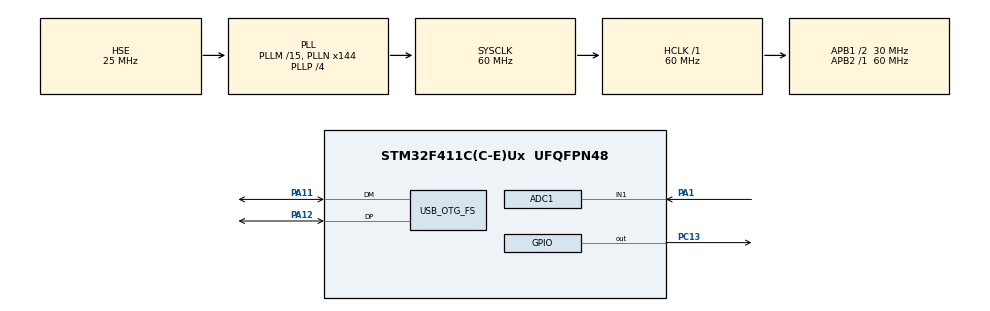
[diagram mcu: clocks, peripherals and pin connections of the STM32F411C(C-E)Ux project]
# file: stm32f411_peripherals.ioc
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ADC1.Channel-0\#ChannelRegularConversion=ADC_CHANNEL_1
ADC1.Channel-1\#ChannelInjectedConversion=ADC_CHANNEL_1
ADC1.ContinuousConvMode=ENABLE
ADC1.InjNumberOfConversion=1
ADC1.InjectedOffset-1\#ChannelInjectedConversion=0
ADC1.InjectedRank-1\#ChannelInjectedConversion=1
ADC1.NbrOfConversionFlag=1
ADC1.Rank-0\#ChannelRegularConversion=1
ADC1.SamplingTime-0\#ChannelRegularConversion=ADC_SAMPLETIME_3CYCLES
ADC1.SamplingTime-1\#ChannelInjectedConversion=ADC_SAMPLETIME_3CYCLES
ADC1.master=1
Mcu.Family=STM32F4
Mcu.Name=STM32F411C(C-E)Ux
Mcu.Package=UFQFPN48
NVIC.ADC_IRQn=true\:0\:0\:false\:false\:true\:true\:true\:true
NVIC.OTG_FS_IRQn=true\:0\:0\:false\:false\:true\:true\:true\:true
NVIC.OTG_FS_WKUP_IRQn=true\:0\:0\:false\:false\:true\:false\:true\:true
NVIC.PriorityGroup=NVIC_PRIORITYGROUP_4
NVIC.TIM1_TRG_COM_TIM11_IRQn=true\:0\:0\:false\:false\:true\:true\:true\:true
PA1.Signal=ADCx_IN1
PA11.Mode=Device_Only
PA11.Signal=USB_OTG_FS_DM
PA12.Mode=Device_Only
PA12.Signal=USB_OTG_FS_DP
PC13-ANTI_TAMP.Signal=GPIO_Output
PC14-OSC32_IN.Mode=LSE-External-Oscillator
PC14-OSC32_IN.Signal=RCC_OSC32_IN
PC15-OSC32_OUT.Mode=LSE-External-Oscillator
PC15-OSC32_OUT.Signal=RCC_OSC32_OUT
PH0\ -\ OSC_IN.Mode=HSE-External-Oscillator
PH0\ -\ OSC_IN.Signal=RCC_OSC_IN
PH1\ -\ OSC_OUT.Mode=HSE-External-Oscillator
PH1\ -\ OSC_OUT.Signal=RCC_OSC_OUT
ProjectManager.HeapSize=0x200
ProjectManager.StackSize=0x400
ProjectManager.TargetToolchain=STM32CubeIDE
RCC.48MHZClocksFreq_Value=48000000
RCC.AHBFreq_Value=60000000
RCC.APB1CLKDivider=RCC_HCLK_DIV2
RCC.APB1Freq_Value=30000000
RCC.APB1TimFreq_Value=60000000
RCC.APB2Freq_Value=60000000
RCC.APB2TimFreq_Value=60000000
RCC.CortexFreq_Value=60000000
RCC.HCLKFreq_Value=60000000
RCC.HSE_VALUE=25000000
RCC.HSI_VALUE=16000000
RCC.PLLM=15
RCC.PLLN=144
RCC.PLLP=RCC_PLLP_DIV4
RCC.PLLQ=5
RCC.RCC_RTC_Clock_Source=RCC_RTCCLKSOURCE_LSI
RCC.RCC_RTC_Clock_SourceVirtual=RCC_RTCCLKSOURCE_LSI
RCC.SYSCLKFreq_VALUE=60000000
RCC.SYSCLKSource=RCC_SYSCLKSOURCE_PLLCLK
RCC.VCOOutputFreq_Value=240000000
SH.ADCx_IN1.0=ADC1_IN1,IN1
TIM11.AutoReloadPreload=TIM_AUTORELOAD_PRELOAD_ENABLE
TIM11.Channel=TIM_CHANNEL_1
TIM11.ClockDivision=TIM_CLOCKDIVISION_DIV1
TIM11.Period=1000
TIM11.Prescaler=1000
USB_DEVICE.CLASS_NAME_FS=CDC
USB_DEVICE.MANUFACTURER_STRING=Bipin
USB_DEVICE.PRODUCT_STRING_CDC_FS=Bipin Virtual ComPort
USB_DEVICE.VirtualMode=Cdc
USB_DEVICE.VirtualModeFS=Cdc_FS
USB_OTG_FS.Sof_enable=ENABLE
USB_OTG_FS.VirtualMode=Device_Only
USB_OTG_FS.low_power_enable=ENABLE
USB_OTG_FS.lpm_enable=ENABLE
VP_TIM11_VS_ClockSourceINT.Mode=Enable_Timer
VP_TIM11_VS_no_output1.Mode=Output Compare1 No Output
VP_USB_DEVICE_VS_USB_DEVICE_CDC_FS.Mode=CDC_FS
board=custom

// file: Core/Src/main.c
/* USER CODE BEGIN Header */
/**
  ******************************************************************************
  * @file           : main.c
  * @brief          : Main program body
  ******************************************************************************
  * @attention
  *
  * Copyright (c) 2025 STMicroelectronics.
  * All rights reserved.
  *
  * This software is licensed under terms that can be found in the LICENSE file
  * in the root directory of this software component.
  * If no LICENSE file comes with this software, it is provided AS-IS.
  *
  ******************************************************************************
  */
/* USER CODE END Header */
#include "main.h"
#include "adc.h"
#include "tim.h"
#include "usb_device.h"
#include "gpio.h"

void SystemClock_Config(void);

int main(void)
{

  /* MCU Configuration--------------------------------------------------------*/

  /* Reset of all peripherals, Initializes the Flash interface and the Systick. */
  HAL_Init();

  /* Configure the system clock */
  SystemClock_Config();

  /* Initialize all configured peripherals */
  MX_GPIO_Init();
  MX_ADC1_Init();
  MX_TIM11_Init();
  MX_USB_DEVICE_Init();
  /* USER CODE BEGIN 2 */
  HAL_TIM_Base_Start_IT(&htim11);
  /* USER CODE END 2 */

  /* Infinite loop */
  while (1)
  {

  }
}

void SystemClock_Config(void)
{
  RCC_OscInitTypeDef RCC_OscInitStruct = {0};
  RCC_ClkInitTypeDef RCC_ClkInitStruct = {0};

  /** Configure the main internal regulator output voltage
  */
  __HAL_RCC_PWR_CLK_ENABLE();
  __HAL_PWR_VOLTAGESCALING_CONFIG(PWR_REGULATOR_VOLTAGE_SCALE1);

  /** Initializes the RCC Oscillators according to the specified parameters
  * in the RCC_OscInitTypeDef structure.
  */
  RCC_OscInitStruct.OscillatorType = RCC_OSCILLATORTYPE_HSE;
  RCC_OscInitStruct.HSEState = RCC_HSE_ON;
  RCC_OscInitStruct.PLL.PLLState = RCC_PLL_ON;
  RCC_OscInitStruct.PLL.PLLSource = RCC_PLLSOURCE_HSE;
  RCC_OscInitStruct.PLL.PLLM = 15;
  RCC_OscInitStruct.PLL.PLLN = 144;
  RCC_OscInitStruct.PLL.PLLP = RCC_PLLP_DIV4;
  RCC_OscInitStruct.PLL.PLLQ = 5;
  if (HAL_RCC_OscConfig(&RCC_OscInitStruct) != HAL_OK)
  {
    Error_Handler();
  }

  /** Initializes the CPU, AHB and APB buses clocks
  */
  RCC_ClkInitStruct.ClockType = RCC_CLOCKTYPE_HCLK|RCC_CLOCKTYPE_SYSCLK
                              |RCC_CLOCKTYPE_PCLK1|RCC_CLOCKTYPE_PCLK2;
  RCC_ClkInitStruct.SYSCLKSource = RCC_SYSCLKSOURCE_PLLCLK;
  RCC_ClkInitStruct.AHBCLKDivider = RCC_SYSCLK_DIV1;
  RCC_ClkInitStruct.APB1CLKDivider = RCC_HCLK_DIV2;
  RCC_ClkInitStruct.APB2CLKDivider = RCC_HCLK_DIV1;

  if (HAL_RCC_ClockConfig(&RCC_ClkInitStruct, FLASH_LATENCY_1) != HAL_OK)
  {
    Error_Handler();
  }
}

/* USER CODE BEGIN 4 */
void HAL_TIM_PeriodElapsedCallback(TIM_HandleTypeDef *htim)
{
    if (htim->Instance == TIM11)
    {
        HAL_GPIO_TogglePin(GPIOC, GPIO_PIN_13);
    }
}

/* USER CODE END 4 */

void Error_Handler(void)
{
  __disable_irq();
  while (1)
  {
  }
}
